AUTOSAR XML (schema 4-3-0)
package /ComponentTypes
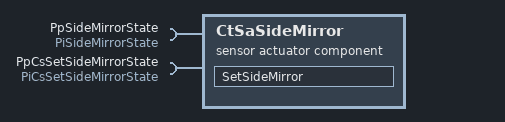
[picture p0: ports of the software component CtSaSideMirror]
  sensor actuator sw component type CtSaSideMirror
    require port PpSideMirrorState: required-interface=PiSideMirrorState
    require port PpCsSetSideMirrorState: required-com-specs=[Operation, WriteToSideMirror], required-interface=PiCsSetSideMirrorState
    behavior CtSaSideMirror_InternalBehavior
      data received event DRT_SetSideMirror_PpSideMirrorState_DeSidMirrorState: start-on-event=SetSideMirror, data=PpSideMirrorState.DeSidMirrorState
      runnable SetSideMirror
        sync call SC_PpCsSetSideMirrorState_WriteToSideMirror: operation=PpCsSetSideMirrorState.WriteToSideMirror
  swc implementation CtSaSideMirror_Implementation: behavior=CtSaSideMirror_InternalBehavior
